# PIC32CM1216LS00100 device description
Architecture: CORTEX-M23; Family: PIC32CM; Series: PIC32CMLS00
Registers are 32-bit, read-write, reset 0x0 unless marked. A register's access mark holds for its fields unless they carry their own. Offsets are from the block's base; [hi:lo] are bit positions; {n}, {i} and the like mark numbered series.

## SCB — System Control Block
Instances: SCB 0xE000ED00, SCB_NS 0xE002ED00
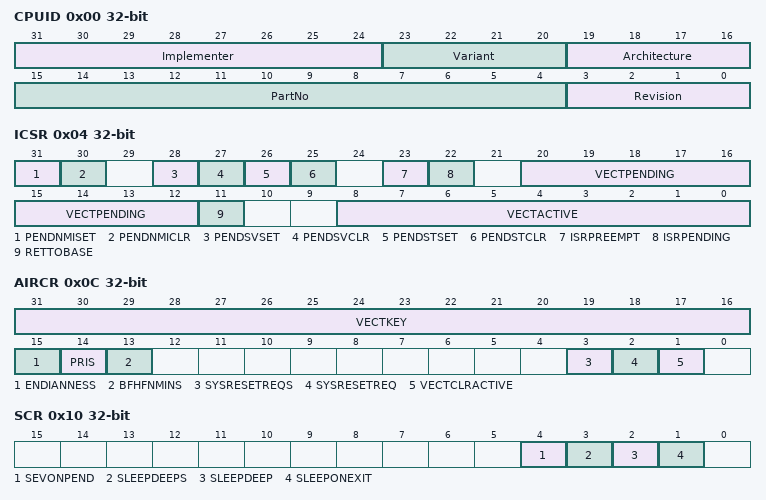
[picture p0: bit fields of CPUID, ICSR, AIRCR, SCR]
0x00 CPUID ro reset not defined — CPUID base register
  [31:24] Implementer — Implementer code, ARM=0x41
  [23:20] Variant — Variant number
  [19:16] Architecture — Architecture version, 0xC=ARMv8-M Base Line, 0xF=ARMv8-M Main Line
  [15:4] PartNo — Part number, 0xD20=Cortex-M23
  [3:0] Revision — Revision number
0x04 ICSR reset not defined — Interrupt Control and State Register
  [31] PENDNMISET
    0=Write: no effect; read: NMI exception is not pending; 1=Write: changes NMI exception state to pending; read: NMI exception is pending
  [30] PENDNMICLR — Pend NMI clear
  [28] PENDSVSET — Pend PendSV set
    0=Write: no effect; read: PendSV exception is not pending; 1=Write: changes PendSV exception state to pending; read: PendSV exception is pending
  [27] PENDSVCLR — Pend PendSV clear
    0=No effect; 1=Removes the pending state from the PendSV exception
  [26] PENDSTSET — Pend SysTick set
    0=Write: no effect; read: SysTick exception is not pending; 1=Write: changes SysTick exception state to pending; read: SysTick exception is pending
  [25] PENDSTCLR — Pend SysTick clear
    0=No effect; 1=Removes the pending state from the SysTick exception
  [23] ISRPREEMPT — Interrupt preempt
  [22] ISRPENDING — Interrupt pending
  [20:12] VECTPENDING — Vector pending
  [11] RETTOBASE — Return to base
  [8:0] VECTACTIVE — Vector active
0x08 VTOR reset not defined — Vector Table Offset Register
  [31:7] TBLOFF — Vector table base offset
0x0C AIRCR reset not defined — Application Interrupt and Reset Control Register
  [31:16] VECTKEY — Register Key (0x05FA)
  [15] ENDIANNESS — Data Endianness, 0=little, 1=big
    0=LITTLE (Little-endian); 1=BIG (Big-endian)
  [14] PRIS — Prioritize Secure Exceptions
    0=SAME (Priority ranges of Secure and Non-secure exceptions are identical); 1=NS_DEPRIO (Non-secure exceptions are de-prioritized)
  [13] BFHFNMINS — BusFault, HardFault and NMI Non-secure enable
    0=SECURE (BusFault, HardFault, and NMI are Secure); 1=NON_SECURE (BusFault and NMI are Non-secure and exceptions can target Non-secure HardFault)
  [3] SYSRESETREQS — System Reset Request Secure only
    0=BOTH (SYSRESETREQ functionality is available to both Security states); 1=SECURE (SYSRESETREQ functionality is only available to Secure state)
  [2] SYSRESETREQ — System Reset Request
    0=NO (Do not request a system reset); 1=YES (Request a system reset)
  [1] VECTCLRACTIVE — Debug: Clear Active State
    0=NO (Do not clear active state); 1=YES (Clear active state)
0x10 SCR reset not defined — System Control Register
  [4] SEVONPEND — Send Event on Pending bit
    0=Only enabled interrupts or events can wakeup the processor, disabled interrupts are excluded; 1=Enabled events and all interrupts, including disabled interrupts, can wakeup the processor
  [3] SLEEPDEEPS — Sleep deep secure
  [2] SLEEPDEEP
    0=Sleep; 1=Deep sleep
  [1] SLEEPONEXIT
    0=O not sleep when returning to Thread mode; 1=Enter sleep, or deep sleep, on return from an ISR
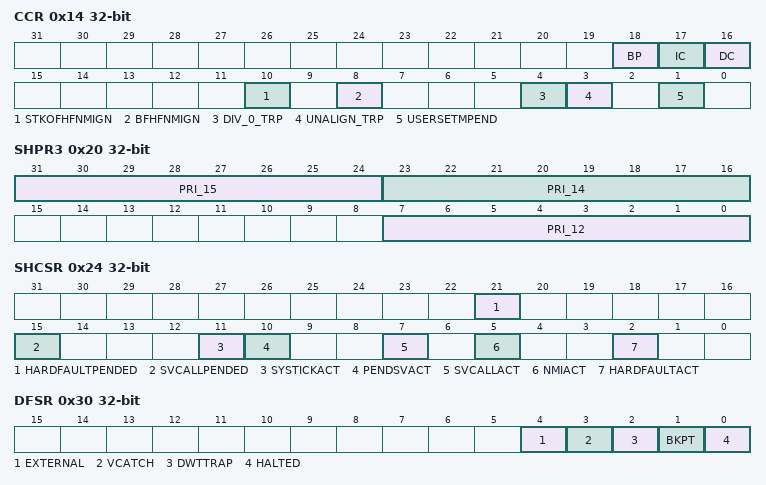
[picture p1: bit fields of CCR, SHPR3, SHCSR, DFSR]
0x14 CCR reset not defined — Configuration and Control Register
  [18] BP — Branch prediction enable
  [17] IC — Instruction cache enable
  [16] DC — Data cache enable
  [10] STKOFHFNMIGN — Stack overflow in HardFault and NMI ignore
  [8] BFHFNMIGN — BusFault in HardFault or NMI ignore
  [4] DIV_0_TRP — Divide by zero trap
  [3] UNALIGN_TRP — Unaligned trap
    0=Do not trap unaligned halfword and word accesses; 1=Trap unaligned halfword and word accesses
  [1] USERSETMPEND — User set main pending
0x1C SHPR2 reset not defined — System Handler Priority Register 2
  [31:24] PRI_11 — Priority of system handler 11, SVCall
0x20 SHPR3 reset not defined — System Handler Priority Register 3
  [31:24] PRI_15 — Priority of system handler 15, SysTick
  [23:16] PRI_14 — Priority of system handler 14, PendSV
  [7:0] PRI_12 — Priority of system handler 12, DebugMonitor
0x24 SHCSR reset not defined — System Handler Control and State Register
  [21] HARDFAULTPENDED — HardFault exception pended state
  [15] SVCALLPENDED — SVCall exception pended state
  [11] SYSTICKACT — SysTick exception active state
  [10] PENDSVACT — PendSV exception active state
  [7] SVCALLACT — SVCall exception active state
  [5] NMIACT — NMI exception active state
  [2] HARDFAULTACT — HardFault exception active state
0x30 DFSR reset not defined — Debug Fault Status Register
  [4] EXTERNAL — External event
  [3] VCATCH — Vector Catch event
  [2] DWTTRAP — Watchpoint event
  [1] BKPT — Breakpoint event
  [0] HALTED — Halt or step event
0x3C AFSR reset not defined — Auxiliary Fault Status Register
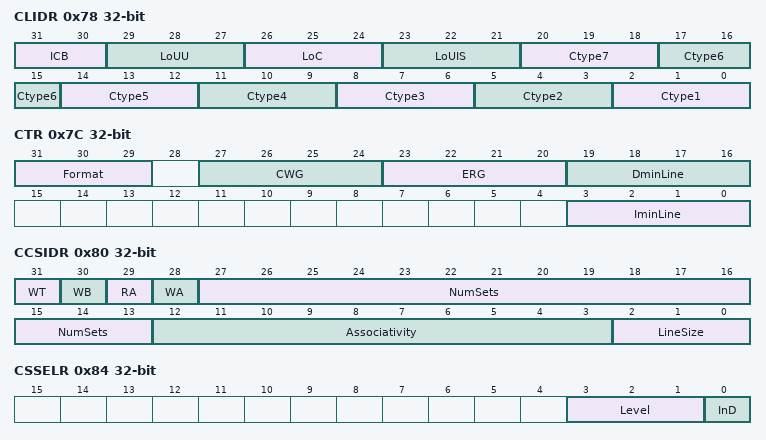
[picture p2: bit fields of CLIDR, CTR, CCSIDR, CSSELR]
0x78 CLIDR ro reset not defined — Cache Level ID Register
  [31:30] ICB — Inner cache boundary
    0=NO (Not disclosed in this mechanism); 1=L1 (L1 cache is the highest inner level); 2=L2 (L2 cache is the highest inner level); 3=L3 (L3 cache is the highest inner level)
  [29:27] LoUU — Level of Unification Uniprocessor
  [26:24] LoC — Level of Coherence
  [23:21] LoUIS — Level of Unification Inner Shareable
  [3n-1:3n-3] Ctype{n} (n=1..7) — Cache type at level {n}
    0=NO (No cache); 1=IC (Instruction cache only); 2=DC (Data cache only); 3=SEPARATE (Separate instruction and data caches); 4=UNIFIED (Unified cache)
0x7C CTR ro reset not defined — Cache Type Register
  [31:29] Format — Cache Type Register format
    0=NO (No cache type information provided); 4=YES (Cache type information is provided)
  [27:24] CWG — Cache Write-back Granule
  [23:20] ERG — Exclusives Reservation Granule
  [19:16] DminLine — Data cache minimum line length
  [3:0] IminLine — Instruction cache minimum line length
0x80 CCSIDR ro reset not defined — Current Cache Size ID register
  [31] WT — Write-Through
  [30] WB — Write-Back
  [29] RA — Read-Allocate
  [28] WA — Write-Allocate
  [27:13] NumSets — Number of sets - 1
  [12:3] Associativity — Associativity - 1
  [2:0] LineSize — log2(number of words per line) - 2
0x84 CSSELR reset not defined — Cache Size Selection Register
  [3:1] Level — Cache level - 1
  [0] InD — Instruction not Data
